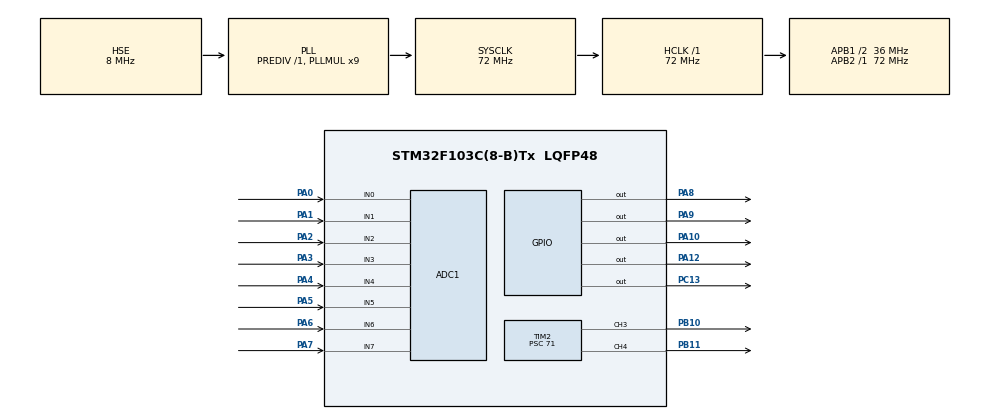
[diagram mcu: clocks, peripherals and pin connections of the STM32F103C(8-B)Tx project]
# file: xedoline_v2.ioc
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ADC1.Channel-0\#ChannelRegularConversion=ADC_CHANNEL_0
ADC1.Channel-1\#ChannelRegularConversion=ADC_CHANNEL_1
ADC1.Channel-2\#ChannelRegularConversion=ADC_CHANNEL_2
ADC1.Channel-3\#ChannelRegularConversion=ADC_CHANNEL_3
ADC1.Channel-4\#ChannelRegularConversion=ADC_CHANNEL_4
ADC1.Channel-5\#ChannelRegularConversion=ADC_CHANNEL_5
ADC1.Channel-6\#ChannelRegularConversion=ADC_CHANNEL_6
ADC1.Channel-7\#ChannelRegularConversion=ADC_CHANNEL_7
ADC1.ContinuousConvMode=ENABLE
ADC1.NbrOfConversion=8
ADC1.NbrOfConversionFlag=1
ADC1.Rank-0\#ChannelRegularConversion=1
ADC1.Rank-1\#ChannelRegularConversion=2
ADC1.Rank-2\#ChannelRegularConversion=3
ADC1.Rank-3\#ChannelRegularConversion=4
ADC1.Rank-4\#ChannelRegularConversion=5
ADC1.Rank-5\#ChannelRegularConversion=6
ADC1.Rank-6\#ChannelRegularConversion=7
ADC1.Rank-7\#ChannelRegularConversion=8
ADC1.SamplingTime-0\#ChannelRegularConversion=ADC_SAMPLETIME_239CYCLES_5
ADC1.SamplingTime-1\#ChannelRegularConversion=ADC_SAMPLETIME_239CYCLES_5
ADC1.SamplingTime-2\#ChannelRegularConversion=ADC_SAMPLETIME_239CYCLES_5
ADC1.SamplingTime-3\#ChannelRegularConversion=ADC_SAMPLETIME_239CYCLES_5
ADC1.SamplingTime-4\#ChannelRegularConversion=ADC_SAMPLETIME_239CYCLES_5
ADC1.SamplingTime-5\#ChannelRegularConversion=ADC_SAMPLETIME_239CYCLES_5
ADC1.SamplingTime-6\#ChannelRegularConversion=ADC_SAMPLETIME_239CYCLES_5
ADC1.SamplingTime-7\#ChannelRegularConversion=ADC_SAMPLETIME_239CYCLES_5
ADC1.master=1
Dma.ADC1.0.Direction=DMA_PERIPH_TO_MEMORY
Dma.ADC1.0.Instance=DMA1_Channel1
Dma.ADC1.0.MemDataAlignment=DMA_MDATAALIGN_HALFWORD
Dma.ADC1.0.MemInc=DMA_MINC_ENABLE
Dma.ADC1.0.Mode=DMA_CIRCULAR
Dma.ADC1.0.PeriphDataAlignment=DMA_PDATAALIGN_HALFWORD
Dma.ADC1.0.PeriphInc=DMA_PINC_DISABLE
Dma.ADC1.0.Priority=DMA_PRIORITY_MEDIUM
Dma.Request0=ADC1
Mcu.Family=STM32F1
Mcu.Name=STM32F103C(8-B)Tx
Mcu.Package=LQFP48
NVIC.DMA1_Channel1_IRQn=true\:0\:0\:false\:false\:true\:false\:true\:true
NVIC.PriorityGroup=NVIC_PRIORITYGROUP_4
NVIC.TIM1_UP_IRQn=true\:1\:0\:true\:false\:true\:true\:true\:true
PA0-WKUP.Signal=ADCx_IN0
PA1.Signal=ADCx_IN1
PA10.Signal=GPIO_Output
PA12.Signal=GPIO_Output
PA13.Mode=Serial_Wire
PA13.Signal=SYS_JTMS-SWDIO
PA14.Mode=Serial_Wire
PA14.Signal=SYS_JTCK-SWCLK
PA2.Signal=ADCx_IN2
PA3.Signal=ADCx_IN3
PA4.Signal=ADCx_IN4
PA5.Signal=ADCx_IN5
PA6.Signal=ADCx_IN6
PA7.Signal=ADCx_IN7
PA8.Signal=GPIO_Output
PA9.Signal=GPIO_Output
PB10.Signal=S_TIM2_CH3
PB11.Signal=S_TIM2_CH4
PC13-TAMPER-RTC.Signal=GPIO_Output
PD0-OSC_IN.Mode=HSE-External-Oscillator
PD0-OSC_IN.Signal=RCC_OSC_IN
PD1-OSC_OUT.Mode=HSE-External-Oscillator
PD1-OSC_OUT.Signal=RCC_OSC_OUT
ProjectManager.HeapSize=0x200
ProjectManager.StackSize=0x400
ProjectManager.TargetToolchain=MDK-ARM V5.32
RCC.ADCPresc=RCC_ADCPCLK2_DIV6
RCC.AHBFreq_Value=72000000
RCC.APB1CLKDivider=RCC_HCLK_DIV2
RCC.APB1Freq_Value=36000000
RCC.APB1TimFreq_Value=72000000
RCC.APB2Freq_Value=72000000
RCC.APB2TimFreq_Value=72000000
RCC.HCLKFreq_Value=72000000
RCC.PLLMUL=RCC_PLL_MUL9
RCC.PLLSourceVirtual=RCC_PLLSOURCE_HSE
RCC.SYSCLKFreq_VALUE=72000000
RCC.SYSCLKSource=RCC_SYSCLKSOURCE_PLLCLK
RCC.USBFreq_Value=72000000
SH.ADCx_IN0.0=ADC1_IN0,IN0
SH.ADCx_IN1.0=ADC1_IN1,IN1
SH.ADCx_IN2.0=ADC1_IN2,IN2
SH.ADCx_IN3.0=ADC1_IN3,IN3
SH.ADCx_IN4.0=ADC1_IN4,IN4
SH.ADCx_IN5.0=ADC1_IN5,IN5
SH.ADCx_IN6.0=ADC1_IN6,IN6
SH.ADCx_IN7.0=ADC1_IN7,IN7
SH.S_TIM2_CH3.0=TIM2_CH3,PWM Generation3 CH3
SH.S_TIM2_CH4.0=TIM2_CH4,PWM Generation4 CH4
TIM1.Period=999
TIM1.Prescaler=71
TIM2.Channel-PWM\ Generation3\ CH3=TIM_CHANNEL_3
TIM2.Channel-PWM\ Generation4\ CH4=TIM_CHANNEL_4
TIM2.Period=999
TIM2.Prescaler=71
VP_TIM1_VS_ClockSourceINT.Mode=Internal
board=custom

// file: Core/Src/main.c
/* USER CODE BEGIN Header */
/**
  ******************************************************************************
  * @file           : main.c
  * @brief          : Main program body
  ******************************************************************************
  * @attention
  *
  * Copyright (c) 2024 STMicroelectronics.
  * All rights reserved.
  *
  * This software is licensed under terms that can be found in the LICENSE file
  * in the root directory of this software component.
  * If no LICENSE file comes with this software, it is provided AS-IS.
  *
  ******************************************************************************
  */
/* USER CODE END Header */
#include "main.h"

/* USER CODE BEGIN Includes */
#include "user.h"
/* USER CODE END Includes */

ADC_HandleTypeDef hadc1;
DMA_HandleTypeDef hdma_adc1;

TIM_HandleTypeDef htim1;
TIM_HandleTypeDef htim2;

/* USER CODE BEGIN PV */
ROBOT my_first_line_follower;
extern ADC ROBOT_linesensor;

/* USER CODE END PV */

void SystemClock_Config(void);
static void MX_GPIO_Init(void);
static void MX_DMA_Init(void);
static void MX_ADC1_Init(void);
static void MX_TIM2_Init(void);
static void MX_TIM1_Init(void);

/* USER CODE BEGIN 0 */
void HAL_TIM_PeriodElapsedCallback(TIM_HandleTypeDef *htim)
{
 timer_handle(&my_first_line_follower);
}
/* USER CODE END 0 */

int main(void)
{

  /* MCU Configuration--------------------------------------------------------*/

  /* Reset of all peripherals, Initializes the Flash interface and the Systick. */
  HAL_Init();

  /* Configure the system clock */
  SystemClock_Config();

  /* Initialize all configured peripherals */
  MX_GPIO_Init();
  MX_DMA_Init();
  MX_ADC1_Init();
  MX_TIM2_Init();
  MX_TIM1_Init();
  /* USER CODE BEGIN 2 */
	/*
	HAL_TIM_Base_Start_IT(&htim1);
	HAL_GPIO_WritePin(GPIOA, GPIO_PIN_8, 1);  // Chân A8 m?c 1
    HAL_GPIO_WritePin(GPIOA, GPIO_PIN_9, 0); // Chân A9 m?c 0
    HAL_GPIO_WritePin(GPIOA, GPIO_PIN_10, 1); // Chân A10 m?c 1
    HAL_GPIO_WritePin(GPIOA, GPIO_PIN_12, 0); // Chân A11 m?c 0
		  HAL_TIM_PWM_Start(&htim2, TIM_CHANNEL_3);
  HAL_TIM_PWM_Start(&htim2, TIM_CHANNEL_4);*/
		robot_init(&my_first_line_follower,&hadc1,&hdma_adc1,&htim2);
		check_black_white(&ROBOT_linesensor);
		HAL_TIM_Base_Start_IT(&htim1);
	//robot_speed(40,40);
  /* USER CODE END 2 */

  /* Infinite loop */
  while (1)
  {

    /* USER CODE BEGIN 3 */
		//robot_speed(50,50);
	control_loop(&my_first_line_follower);

		/*
		HAL_GPIO_WritePin(GPIOC, GPIO_PIN_13, GPIO_PIN_SET); // Chân A10 m?c 1
		 __HAL_TIM_SET_COMPARE(&htim2, TIM_CHANNEL_3, 1000); // 1000/ARR
    __HAL_TIM_SET_COMPARE(&htim2, TIM_CHANNEL_4, 2000); // 2000/ARR
				HAL_Delay(500);
     // Chân A11 m?c 0
		    __HAL_TIM_SET_COMPARE(&htim2, TIM_CHANNEL_3, 2000); // 2000/ARR
    __HAL_TIM_SET_COMPARE(&htim2, TIM_CHANNEL_4, 1000); // 1000/ARR
		HAL_Delay(500);*/
  }
  /* USER CODE END 3 */
}

void SystemClock_Config(void)
{
  RCC_OscInitTypeDef RCC_OscInitStruct = {0};
  RCC_ClkInitTypeDef RCC_ClkInitStruct = {0};
  RCC_PeriphCLKInitTypeDef PeriphClkInit = {0};

  /** Initializes the RCC Oscillators according to the specified parameters
  * in the RCC_OscInitTypeDef structure.
  */
  RCC_OscInitStruct.OscillatorType = RCC_OSCILLATORTYPE_HSE;
  RCC_OscInitStruct.HSEState = RCC_HSE_ON;
  RCC_OscInitStruct.HSEPredivValue = RCC_HSE_PREDIV_DIV1;
  RCC_OscInitStruct.HSIState = RCC_HSI_ON;
  RCC_OscInitStruct.PLL.PLLState = RCC_PLL_ON;
  RCC_OscInitStruct.PLL.PLLSource = RCC_PLLSOURCE_HSE;
  RCC_OscInitStruct.PLL.PLLMUL = RCC_PLL_MUL9;
  if (HAL_RCC_OscConfig(&RCC_OscInitStruct) != HAL_OK)
  {
    Error_Handler();
  }

  /** Initializes the CPU, AHB and APB buses clocks
  */
  RCC_ClkInitStruct.ClockType = RCC_CLOCKTYPE_HCLK|RCC_CLOCKTYPE_SYSCLK
                              |RCC_CLOCKTYPE_PCLK1|RCC_CLOCKTYPE_PCLK2;
  RCC_ClkInitStruct.SYSCLKSource = RCC_SYSCLKSOURCE_PLLCLK;
  RCC_ClkInitStruct.AHBCLKDivider = RCC_SYSCLK_DIV1;
  RCC_ClkInitStruct.APB1CLKDivider = RCC_HCLK_DIV2;
  RCC_ClkInitStruct.APB2CLKDivider = RCC_HCLK_DIV1;

  if (HAL_RCC_ClockConfig(&RCC_ClkInitStruct, FLASH_LATENCY_2) != HAL_OK)
  {
    Error_Handler();
  }
  PeriphClkInit.PeriphClockSelection = RCC_PERIPHCLK_ADC;
  PeriphClkInit.AdcClockSelection = RCC_ADCPCLK2_DIV6;
  if (HAL_RCCEx_PeriphCLKConfig(&PeriphClkInit) != HAL_OK)
  {
    Error_Handler();
  }
}

static void MX_ADC1_Init(void)
{

  ADC_ChannelConfTypeDef sConfig = {0};

  /** Common config
  */
  hadc1.Instance = ADC1;
  hadc1.Init.ScanConvMode = ADC_SCAN_ENABLE;
  hadc1.Init.ContinuousConvMode = ENABLE;
  hadc1.Init.DiscontinuousConvMode = DISABLE;
  hadc1.Init.ExternalTrigConv = ADC_SOFTWARE_START;
  hadc1.Init.DataAlign = ADC_DATAALIGN_RIGHT;
  hadc1.Init.NbrOfConversion = 8;
  if (HAL_ADC_Init(&hadc1) != HAL_OK)
  {
    Error_Handler();
  }

  /** Configure Regular Channel
  */
  sConfig.Channel = ADC_CHANNEL_0;
  sConfig.Rank = ADC_REGULAR_RANK_1;
  sConfig.SamplingTime = ADC_SAMPLETIME_239CYCLES_5;
  if (HAL_ADC_ConfigChannel(&hadc1, &sConfig) != HAL_OK)
  {
    Error_Handler();
  }

  /** Configure Regular Channel
  */
  sConfig.Channel = ADC_CHANNEL_1;
  sConfig.Rank = ADC_REGULAR_RANK_2;
  if (HAL_ADC_ConfigChannel(&hadc1, &sConfig) != HAL_OK)
  {
    Error_Handler();
  }

  /** Configure Regular Channel
  */
  sConfig.Channel = ADC_CHANNEL_2;
  sConfig.Rank = ADC_REGULAR_RANK_3;
  if (HAL_ADC_ConfigChannel(&hadc1, &sConfig) != HAL_OK)
  {
    Error_Handler();
  }

  /** Configure Regular Channel
  */
  sConfig.Channel = ADC_CHANNEL_3;
  sConfig.Rank = ADC_REGULAR_RANK_4;
  if (HAL_ADC_ConfigChannel(&hadc1, &sConfig) != HAL_OK)
  {
    Error_Handler();
  }

  /** Configure Regular Channel
  */
  sConfig.Channel = ADC_CHANNEL_4;
  sConfig.Rank = ADC_REGULAR_RANK_5;
  if (HAL_ADC_ConfigChannel(&hadc1, &sConfig) != HAL_OK)
  {
    Error_Handler();
  }

  /** Configure Regular Channel
  */
  sConfig.Channel = ADC_CHANNEL_5;
  sConfig.Rank = ADC_REGULAR_RANK_6;
  if (HAL_ADC_ConfigChannel(&hadc1, &sConfig) != HAL_OK)
  {
    Error_Handler();
  }

  /** Configure Regular Channel
  */
  sConfig.Channel = ADC_CHANNEL_6;
  sConfig.Rank = ADC_REGULAR_RANK_7;
  if (HAL_ADC_ConfigChannel(&hadc1, &sConfig) != HAL_OK)
  {
    Error_Handler();
  }

  /** Configure Regular Channel
  */
  sConfig.Channel = ADC_CHANNEL_7;
  sConfig.Rank = ADC_REGULAR_RANK_8;
  if (HAL_ADC_ConfigChannel(&hadc1, &sConfig) != HAL_OK)
  {
    Error_Handler();
  }

}

static void MX_TIM1_Init(void)
{

  TIM_ClockConfigTypeDef sClockSourceConfig = {0};
  TIM_MasterConfigTypeDef sMasterConfig = {0};

  htim1.Instance = TIM1;
  htim1.Init.Prescaler = 71;
  htim1.Init.CounterMode = TIM_COUNTERMODE_UP;
  htim1.Init.Period = 999;
  htim1.Init.ClockDivision = TIM_CLOCKDIVISION_DIV1;
  htim1.Init.RepetitionCounter = 0;
  htim1.Init.AutoReloadPreload = TIM_AUTORELOAD_PRELOAD_DISABLE;
  if (HAL_TIM_Base_Init(&htim1) != HAL_OK)
  {
    Error_Handler();
  }
  sClockSourceConfig.ClockSource = TIM_CLOCKSOURCE_INTERNAL;
  if (HAL_TIM_ConfigClockSource(&htim1, &sClockSourceConfig) != HAL_OK)
  {
    Error_Handler();
  }
  sMasterConfig.MasterOutputTrigger = TIM_TRGO_RESET;
  sMasterConfig.MasterSlaveMode = TIM_MASTERSLAVEMODE_DISABLE;
  if (HAL_TIMEx_MasterConfigSynchronization(&htim1, &sMasterConfig) != HAL_OK)
  {
    Error_Handler();
  }

}

static void MX_TIM2_Init(void)
{

  TIM_MasterConfigTypeDef sMasterConfig = {0};
  TIM_OC_InitTypeDef sConfigOC = {0};

  htim2.Instance = TIM2;
  htim2.Init.Prescaler = 71;
  htim2.Init.CounterMode = TIM_COUNTERMODE_UP;
  htim2.Init.Period = 999;
  htim2.Init.ClockDivision = TIM_CLOCKDIVISION_DIV1;
  htim2.Init.AutoReloadPreload = TIM_AUTORELOAD_PRELOAD_DISABLE;
  if (HAL_TIM_PWM_Init(&htim2) != HAL_OK)
  {
    Error_Handler();
  }
  sMasterConfig.MasterOutputTrigger = TIM_TRGO_RESET;
  sMasterConfig.MasterSlaveMode = TIM_MASTERSLAVEMODE_DISABLE;
  if (HAL_TIMEx_MasterConfigSynchronization(&htim2, &sMasterConfig) != HAL_OK)
  {
    Error_Handler();
  }
  sConfigOC.OCMode = TIM_OCMODE_PWM1;
  sConfigOC.Pulse = 0;
  sConfigOC.OCPolarity = TIM_OCPOLARITY_HIGH;
  sConfigOC.OCFastMode = TIM_OCFAST_DISABLE;
  if (HAL_TIM_PWM_ConfigChannel(&htim2, &sConfigOC, TIM_CHANNEL_3) != HAL_OK)
  {
    Error_Handler();
  }
  if (HAL_TIM_PWM_ConfigChannel(&htim2, &sConfigOC, TIM_CHANNEL_4) != HAL_OK)
  {
    Error_Handler();
  }
  HAL_TIM_MspPostInit(&htim2);

}

static void MX_DMA_Init(void)
{

  /* DMA controller clock enable */
  __HAL_RCC_DMA1_CLK_ENABLE();

  /* DMA interrupt init */
  /* DMA1_Channel1_IRQn interrupt configuration */
  HAL_NVIC_SetPriority(DMA1_Channel1_IRQn, 0, 0);
  HAL_NVIC_EnableIRQ(DMA1_Channel1_IRQn);

}

static void MX_GPIO_Init(void)
{
  GPIO_InitTypeDef GPIO_InitStruct = {0};

  /* GPIO Ports Clock Enable */
  __HAL_RCC_GPIOC_CLK_ENABLE();
  __HAL_RCC_GPIOD_CLK_ENABLE();
  __HAL_RCC_GPIOA_CLK_ENABLE();
  __HAL_RCC_GPIOB_CLK_ENABLE();

  /*Configure GPIO pin Output Level */
  HAL_GPIO_WritePin(GPIOC, GPIO_PIN_13, GPIO_PIN_RESET);

  /*Configure GPIO pin Output Level */
  HAL_GPIO_WritePin(GPIOA, GPIO_PIN_8|GPIO_PIN_9|GPIO_PIN_10|GPIO_PIN_12, GPIO_PIN_RESET);

  /*Configure GPIO pin : PC13 */
  GPIO_InitStruct.Pin = GPIO_PIN_13;
  GPIO_InitStruct.Mode = GPIO_MODE_OUTPUT_PP;
  GPIO_InitStruct.Pull = GPIO_NOPULL;
  GPIO_InitStruct.Speed = GPIO_SPEED_FREQ_LOW;
  HAL_GPIO_Init(GPIOC, &GPIO_InitStruct);

  /*Configure GPIO pins : PA8 PA9 PA10 PA12 */
  GPIO_InitStruct.Pin = GPIO_PIN_8|GPIO_PIN_9|GPIO_PIN_10|GPIO_PIN_12;
  GPIO_InitStruct.Mode = GPIO_MODE_OUTPUT_PP;
  GPIO_InitStruct.Pull = GPIO_NOPULL;
  GPIO_InitStruct.Speed = GPIO_SPEED_FREQ_LOW;
  HAL_GPIO_Init(GPIOA, &GPIO_InitStruct);

}

void Error_Handler(void)
{
  __disable_irq();
  while (1)
  {
  }
}
